# R7FA2A1AB register map
Vendor: Renesas; Series: RA2; File version: 1.1
CPU: CM23 r1p0, little endian, MPU, no FPU, VTOR, 2 interrupt priority bits
Registers are 8-bit, read-write, reset 0x0 unless marked. A register's access mark holds for its fields unless they carry their own. Offsets are from the block's base; [hi:lo] are bit positions; {n}, {i} and the like mark numbered series; 'fields as' and 'values as' point back to an identical list.

## MMF — Memory Mirror Function
Base 0x40001000
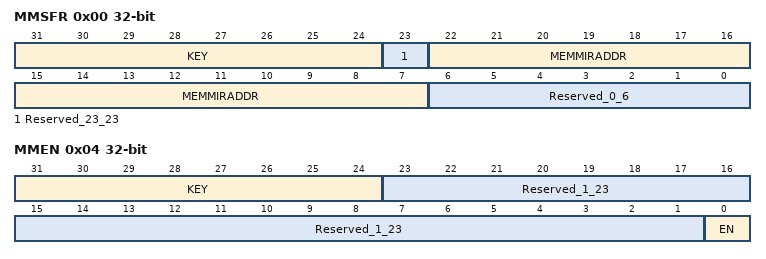
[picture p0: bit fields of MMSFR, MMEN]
0x00 MMSFR 32-bit — MemMirror Special Function Register
  [31:24] KEY wo — MMSFR Key Code
  [23] Reserved_23_23 — This bit is read as 0. The write value should be 0.
  [22:7] MEMMIRADDR — Specifies the memory mirror address.NOTE: A value cannot be set in the low,order 7 bits. These bits are fixed to 0.
  [6:0] Reserved_0_6 — These bits are read as 0000000. The write value should be 0000000.
0x04 MMEN 32-bit — MemMirror Enable Register
  [31:24] KEY wo — MMEN Key Code
  [23:1] Reserved_1_23 — These bits are read as 00000000000000000000000. The write value should be 00000000000000000000000.
  [0] EN — Memory Mirror Function Enable

## MMPU — Bus Master MPU
Base 0x40000000
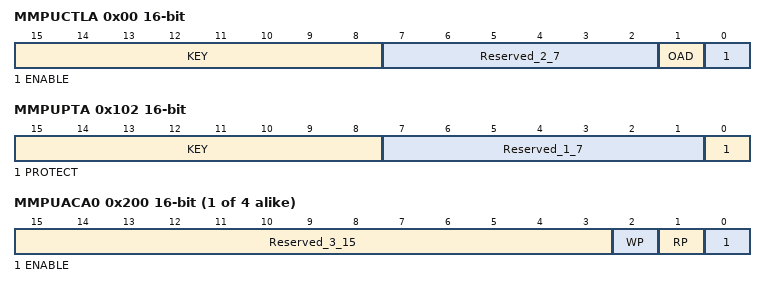
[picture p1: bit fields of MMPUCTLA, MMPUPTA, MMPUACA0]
0x00 MMPUCTLA 16-bit — Bus Master MPU Control Register
  [15:8] KEY wo — Write Keyword The data written to these bits are not stored.
  [7:2] Reserved_2_7 — These bits are read as 000000. The write value should be 000000.
  [1] OAD — Operation After Detection
  [0] ENABLE — Master Group Enable
0x102 MMPUPTA 16-bit — Group A Protection of Register
  [15:8] KEY wo — Write Keyword The data written to these bits are not stored.
  [7:1] Reserved_1_7 — These bits are read as 0000000. The write value should be 0000000.
  [0] PROTECT — Protection of register(MMPUSAn, MMPUEAn, MMPUACAn and MMPUCTLA )
{0x200+0x10*i} MMPUACA{i} (i=0..3) 16-bit — Group A Region {i} Access Control Register
  [15:3] Reserved_3_15 — These bits are read as 0000000000000. The write value should be 0000000000000.
  [2] WP — Write protection
  [1] RP — Read protection
  [0] ENABLE — Region enable
{0x204+0x10*i} MMPUSA{i} (i=0..3) 32-bit (reset mask 0x3) — Group A Region {i} Start Address Register
  [31:0] MMPUSA — Address where the region starts, for use in region determination.NOTE: The low,order 2 bits are fixed to 0.
  [1:0] Reserved_0_1 — These bits are read as 00. The write value should be 00.
{0x208+0x10*i} MMPUEA{i} (i=0..3) 32-bit reset 0x3 (reset mask 0x3) — Group A Region {i} End Address Register
  [31:0] MMPUEA — Region end address registerAddress where the region end, for use in region determination.NOTE: The low,order 2 bits are fixed to 1.
  [1:0] Reserved_0_1 — These bits are read as 11. The write value should be 11.

## SMPU — Bus Slave MPU
Base 0x40000C00
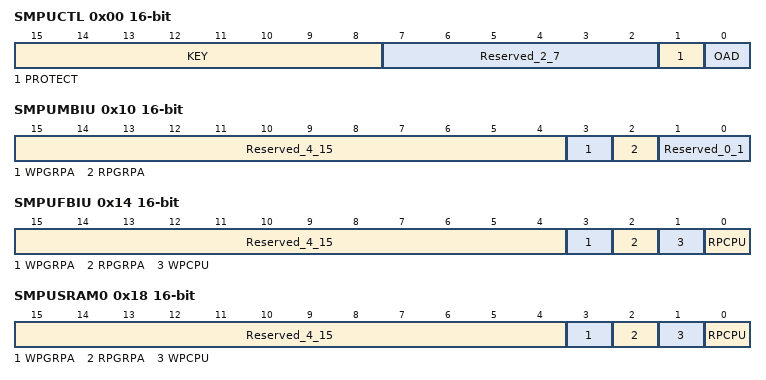
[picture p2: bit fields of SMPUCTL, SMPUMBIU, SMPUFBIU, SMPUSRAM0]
0x00 SMPUCTL 16-bit — Slave MPU Control Register
  [15:8] KEY wo — Key Code This bit is used to enable or disable writing of the PROTECT and OAD bit.
  [7:2] Reserved_2_7 — These bits are read as 000000. The write value should be 000000.
  [1] PROTECT — Protection of register
  [0] OAD — Operation after detection
0x10 SMPUMBIU 16-bit — Access Control Register for MBIU
  [15:4] Reserved_4_15 — These bits are read as 000000000000. The write value should be 000000000000.
  [3] WPGRPA — Master Group A Write protection
  [2] RPGRPA — Master Group A Read protection
  [1:0] Reserved_0_1 — These bits are read as 00. The write value should be 00.
0x14 SMPUFBIU 16-bit — Access Control Register for FBIU
  [15:4] Reserved_4_15 — These bits are read as 000000000000. The write value should be 000000000000.
  [3] WPGRPA — Master Group A Write protection
  [2] RPGRPA — Master Group A Read protection
  [1] WPCPU — CPU Write protection
  [0] RPCPU — CPU Read protection
0x18 SMPUSRAM0 16-bit — Access Control Register for SRAM
  fields as SMPUFBIU
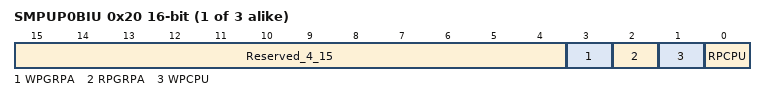
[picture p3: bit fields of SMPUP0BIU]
0x20 SMPUP{x}BIU (x=0,2,6; step 0x4) 16-bit — Access Control Register for P{x}BIU
  fields as SMPUFBIU

## SPMON — CPU Stack Pointer Monitor
Base 0x40000D00
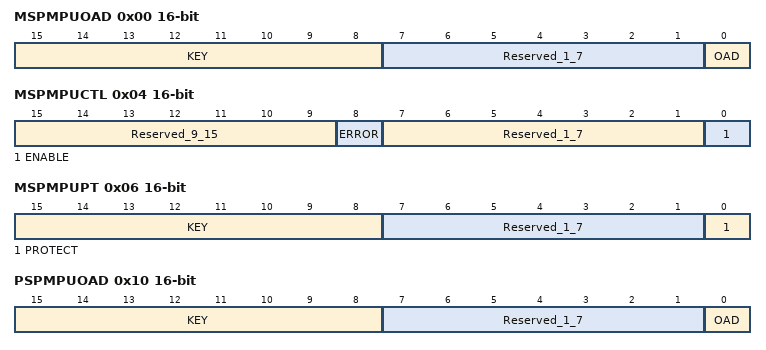
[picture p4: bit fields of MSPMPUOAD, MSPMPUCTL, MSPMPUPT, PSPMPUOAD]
0x00 MSPMPUOAD 16-bit — Stack Pointer Monitor Operation After Detection Register
  [15:8] KEY wo — Write Keyword The data written to these bits are not stored.
  [7:1] Reserved_1_7 — These bits are read as 0000000. The write value should be 0000000.
  [0] OAD — Operation after detection
0x04 MSPMPUCTL 16-bit (reset mask 0xFEFF) — Stack Pointer Monitor Access Control Register
  [15:9] Reserved_9_15 — These bits are read as 0000000. The write value should be 0000000.
  [8] ERROR ro — SP_main monitor error flag
  [7:1] Reserved_1_7 — These bits are read as 0000000. The write value should be 0000000.
  [0] ENABLE — SP_main monitor enable
0x06 MSPMPUPT 16-bit — Stack Pointer Monitor Protection Register
  [15:8] KEY wo — Write Keyword The data written to these bits are not stored.
  [7:1] Reserved_1_7 — These bits are read as 0000000. The write value should be 0000000.
  [0] PROTECT — Protection of register (MSPMPUAC, MSPMPUSA and MSPMPUSE)
0x08 MSPMPUSA 32-bit (reset mask 0x3) — Main Stack Pointer Monitor Start Address Register
  [31:0] MSPMPUSA range 0x1FF00000..0x200FFFFC — Region start address register Address where the region starts, for use in region determination.NOTE: Range: 0x1FF00000-0x200FFFFC The low,order 2 bits are fixed to 0.
0x0C MSPMPUEA 32-bit reset 0x3 (reset mask 0x3) — Main Stack Pointer Monitor End Address Register
  [31:0] MSPMPUEA range 0x1FF00003..0x200FFFFF — Region end address register Address where the region starts, for use in region determination.NOTE: Range: 0x1FF00003-0x200FFFFF The low,order 2 bits are fixed to 1.
0x10 PSPMPUOAD 16-bit — Stack Pointer Monitor Operation After Detection Register
  fields as MSPMPUOAD
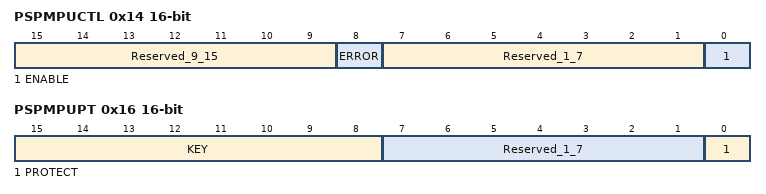
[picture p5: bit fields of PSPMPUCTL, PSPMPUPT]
0x14 PSPMPUCTL 16-bit (reset mask 0xFEFF) — Stack Pointer Monitor Access Control Register
  [15:9] Reserved_9_15 — These bits are read as 0000000. The write value should be 0000000.
  [8] ERROR ro — SP_process monitor error flag
  [7:1] Reserved_1_7 — These bits are read as 0000000. The write value should be 0000000.
  [0] ENABLE — SP_process monitor enable
0x16 PSPMPUPT 16-bit — Stack Pointer Monitor Protection Register
  [15:8] KEY wo — Write Keyword The data written to these bits are not stored.
  [7:1] Reserved_1_7 — These bits are read as 0000000. The write value should be 0000000.
  [0] PROTECT — Protection of register (PSPMPUAC, PSPMPUSA and PSPMPUSE)
0x18 PSPMPUSA 32-bit (reset mask 0x3) — Process Stack Pointer Monitor Start Address Register
  [31:0] PSPMPUSA range 0x1FF00000..0x200FFFFC — Region start address register Address where the region starts, for use in region determination.NOTE: Range: 0x1FF00000-0x200FFFFC The low,order 2 bits are fixed to 0.
0x1C PSPMPUEA 32-bit reset 0x3 (reset mask 0x3) — Process Stack Pointer Monitor End Address Register
  [31:0] PSPMPUEA range 0x1FF00003..0x200FFFFF — Region end address register Address where the region starts, for use in region determination.NOTE: Range: 0x1FF00003-0x200FFFFF The low,order 2 bits are fixed to 1.
